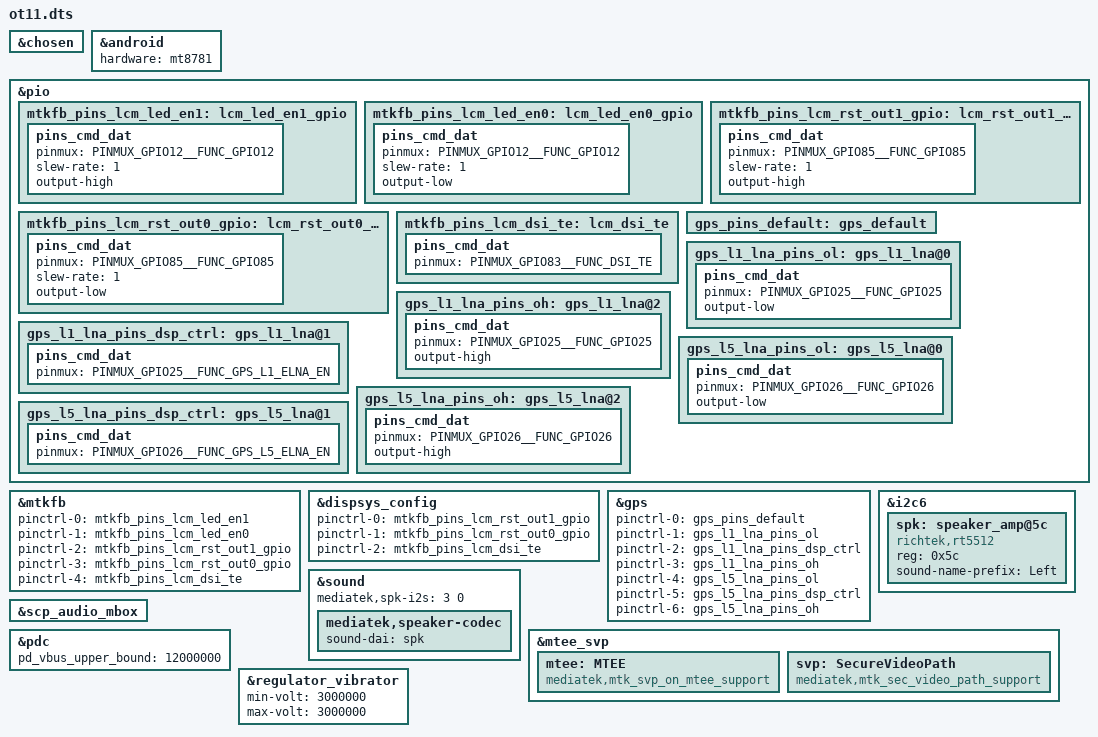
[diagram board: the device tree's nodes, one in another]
// SPDX-License-Identifier: (GPL-2.0 OR MIT)
/*
 * Copyright (C) 2021 MediaTek Inc.
 */

#include <dt-bindings/interrupt-controller/arm-gic.h>
#include <dt-bindings/interrupt-controller/irq.h>
#include <dt-bindings/pinctrl/mt6789-pinfunc.h>
#include "mediatek/cust_mt6789_camera.dtsi"

&chosen {

};

&android {
	hardware = "mt8781";
};

&pio {
	mtkfb_pins_lcm_led_en1: lcm_led_en1_gpio {
		pins_cmd_dat {
			pinmux = <PINMUX_GPIO12__FUNC_GPIO12>;
			slew-rate = <1>;
			output-high;
		};
	};

	mtkfb_pins_lcm_led_en0: lcm_led_en0_gpio {
		pins_cmd_dat {
			pinmux = <PINMUX_GPIO12__FUNC_GPIO12>;
			slew-rate = <1>;
			output-low;
		};
	};

	mtkfb_pins_lcm_rst_out1_gpio: lcm_rst_out1_gpio {
		pins_cmd_dat {
			pinmux = <PINMUX_GPIO85__FUNC_GPIO85>;
			slew-rate = <1>;
			output-high;
		};
	};

	mtkfb_pins_lcm_rst_out0_gpio: lcm_rst_out0_gpio {
		pins_cmd_dat {
			pinmux = <PINMUX_GPIO85__FUNC_GPIO85>;
			slew-rate = <1>;
			output-low;
		};
	};
	mtkfb_pins_lcm_dsi_te: lcm_dsi_te {
		pins_cmd_dat {
			pinmux = <PINMUX_GPIO83__FUNC_DSI_TE>;
		};
	};
};

&mtkfb {
	pinctrl-names = "lcm_led_en1_gpio", "lcm_led_en0_gpio",
		"lcm_rst_out1_gpio", "lcm_rst_out0_gpio",
		"mode_te_te";
	pinctrl-0 = <&mtkfb_pins_lcm_led_en1>;
	pinctrl-1 = <&mtkfb_pins_lcm_led_en0>;
	pinctrl-2 = <&mtkfb_pins_lcm_rst_out1_gpio>;
	pinctrl-3 = <&mtkfb_pins_lcm_rst_out0_gpio>;
	pinctrl-4 = <&mtkfb_pins_lcm_dsi_te>;
	status = "okay";
};

&dispsys_config {
	pinctrl-names =
		"lcm_rst_out1_gpio", "lcm_rst_out0_gpio",
		"mode_te_te";
	pinctrl-0 = <&mtkfb_pins_lcm_rst_out1_gpio>;
	pinctrl-1 = <&mtkfb_pins_lcm_rst_out0_gpio>;
	pinctrl-2 = <&mtkfb_pins_lcm_dsi_te>;
	status = "okay";
};

/* GPS GPIO standardization start */
&pio {
	gps_pins_default: gps_default {
	};
	gps_l1_lna_pins_ol: gps_l1_lna@0 {
		pins_cmd_dat {
			pinmux = <PINMUX_GPIO25__FUNC_GPIO25>;
			output-low;
		};
	};
	gps_l1_lna_pins_dsp_ctrl: gps_l1_lna@1 {
		pins_cmd_dat {
			pinmux = <PINMUX_GPIO25__FUNC_GPS_L1_ELNA_EN>;
		};
	};
	gps_l1_lna_pins_oh: gps_l1_lna@2 {
		pins_cmd_dat {
			pinmux = <PINMUX_GPIO25__FUNC_GPIO25>;
			output-high;
		};
	};
	gps_l5_lna_pins_ol: gps_l5_lna@0 {
		pins_cmd_dat {
			pinmux = <PINMUX_GPIO26__FUNC_GPIO26>;
			output-low;
		};
	};
	gps_l5_lna_pins_dsp_ctrl: gps_l5_lna@1 {
		pins_cmd_dat {
			pinmux = <PINMUX_GPIO26__FUNC_GPS_L5_ELNA_EN>;
		};
	};
	gps_l5_lna_pins_oh: gps_l5_lna@2 {
		pins_cmd_dat {
			pinmux = <PINMUX_GPIO26__FUNC_GPIO26>;
			output-high;
		};
	};
};
&gps {
	pinctrl-names = "default",
		"gps_l1_lna_disable",
		"gps_l1_lna_dsp_ctrl",
		"gps_l1_lna_enable",
		"gps_l5_lna_disable",
		"gps_l5_lna_dsp_ctrl",
		"gps_l5_lna_enable";
	pinctrl-0 = <&gps_pins_default>;
	pinctrl-1 = <&gps_l1_lna_pins_ol>;
	pinctrl-2 = <&gps_l1_lna_pins_dsp_ctrl>;
	pinctrl-3 = <&gps_l1_lna_pins_oh>;
	pinctrl-4 = <&gps_l5_lna_pins_ol>;
	pinctrl-5 = <&gps_l5_lna_pins_dsp_ctrl>;
	pinctrl-6 = <&gps_l5_lna_pins_oh>;
	status = "okay";
};
/* GPS GPIO standardization end */

#include "mediatek/cust_mt6789_camera_v4l2.dtsi"

&i2c6 {
	spk: speaker_amp@5c {
		compatible = "richtek,rt5512";
		#sound-dai-cells = <0>;
		reg = <0x5c>;
		status = "okay";
		sound-name-prefix = "Left";
	};
};

&sound {
	mediatek,spk-i2s = <3 0>;
	mediatek,speaker-codec {
		sound-dai = <&spk>;
	};
};

&scp_audio_mbox {
	status = "okay";
};

&pdc {
	pd_vbus_upper_bound = <12000000>;
};

/*svp start*/
&mtee_svp {
	mtee: MTEE {
		compatible = "mediatek,mtk_svp_on_mtee_support";
	};

	svp: SecureVideoPath {
		compatible = "mediatek,mtk_sec_video_path_support";
	};
};

/*Tab A9 code for SR-AX6739A-01-289 by zhangziyi at 20230426 start*/
&regulator_vibrator {
	min-volt = <3000000>;
	max-volt = <3000000>;
};
/*Tab A9 code for SR-AX6739A-01-289 by zhangziyi at 20230426 end*/
/*svp end*/
/*Tab A9 code for AX6739A-9 by xiongxiaoliang at 20230420 start*/
#include "ot11/cust.dtsi"
/*Tab A9 code for AX6739A-9 by xiongxiaoliang at 20230420 end*/
/*Tab A9 code for AX6739A-9 by wenyaqi at 20230421 start*/
#include "ot11/ot11_common.dtsi"
/*Tab A9 code for AX6739A-9 by wenyaqi at 20230421 end*/
/*End of this file, DO NOT ADD ANYTHING HERE*/
